# nrf9230_engb_celldsp register map
Vendor: Nordic Semiconductor; Series: nRF92; File version: 1
Registers are 32-bit, read-write, reset 0x0 unless marked. A register's access mark holds for its fields unless they carry their own. Offsets are from the block's base; [hi:lo] are bit positions; lines under a group give offsets from that group; {n}, {i} and the like mark numbered series; 'fields as' and 'values as' point back to an identical list.

## PPIBUS — Programmable Peripheral Interconnect Bus
Base 0x45007000
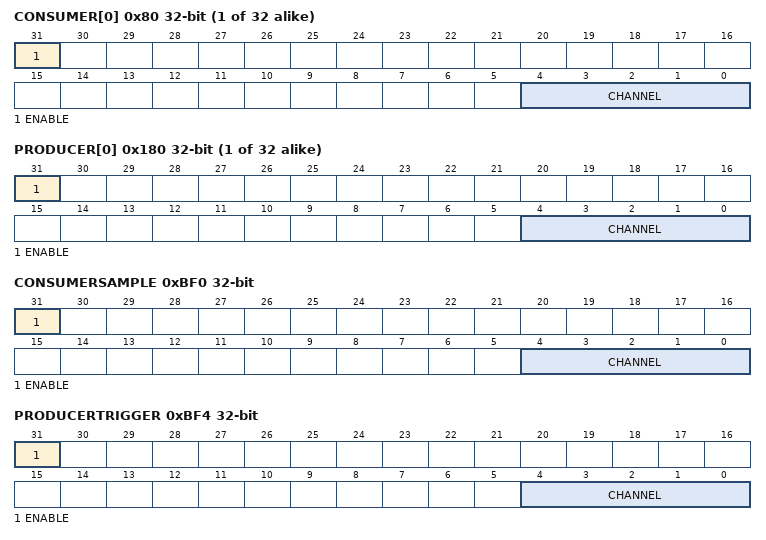
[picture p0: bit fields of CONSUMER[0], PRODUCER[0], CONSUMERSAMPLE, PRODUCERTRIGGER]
{0x80+4i} CONSUMER[{i}] (i=0..31) — Description collection: Configuration for consumer n
  [31] ENABLE — Enable bit for consumer n
  [4:0] CHANNEL — Channel select for consumer n
{0x180+4i} PRODUCER[{i}] (i=0..31) — Description collection: Configuration for producer n
  [31] ENABLE — Enable bit for producer n
  [4:0] CHANNEL — Channel select for producer n
0xBF0 CONSUMERSAMPLE — Configuration for consumer sample register
  [31] ENABLE — Enable bit for consumer sample.
  [4:0] CHANNEL — Channel select for consumer sample.
0xBF4 PRODUCERTRIGGER — Configuration for producer trigger register
  [31] ENABLE — Enable bit for producer trigger.
  [4:0] CHANNEL — Channel select for producer trigger.
0xBF8 SAMPLETASK
  [0] SAMPLETASK — Will sample incoming pulse on ppiBusConsumer[CONSUMERSAMPLE]. Cleared by writing 1'b0.
0xBFC TRIGGEREVENT wo
  [0] TRIGGEREVENT — Will trigger pulse on ppiBusProducer[PRODUCERTRIGGER].

## DSPINTMAP — DSP interrupt mapper
Base 0x45008000
0x504 OFFSET reset 0x100000 — Address offset for IRQ destination address
0x508 ADDRESSINCREMENT reset 0x200 — Address increment for IRQ destination address
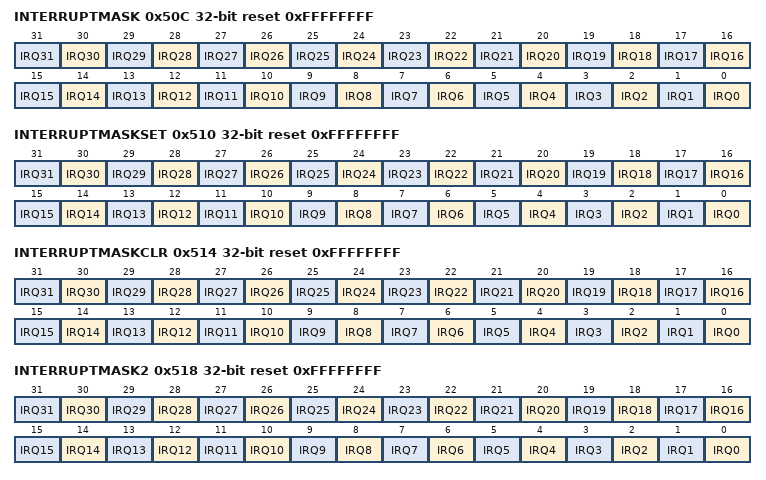
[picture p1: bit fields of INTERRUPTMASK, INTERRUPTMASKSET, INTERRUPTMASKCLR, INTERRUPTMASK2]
0x50C INTERRUPTMASK reset 0xFFFFFFFF — Write interrupt mask for interrupts 0 to 31
  [all] fields
    0=Low (IRQ[i] is unmasked); 1=High (IRQ[i] is masked)
  [n] IRQ{n} (n=0..31) — Mask or unmask interrupt IRQ[i]
0x510 INTERRUPTMASKSET reset 0xFFFFFFFF write-1-sets — Set individual mask bits in interrupt mask for interrupts 0 to 31
  [all] fields
    on read: 0=Low (Read: IRQ[i] is unmasked); 1=High (Read: IRQ[i] is masked) | on write: 1=Set (Write: writing a '1' sets the mask on; writing a '0' has no effect)
  [n] IRQ{n} (n=0..31) — Write '1' to mask IRQ[i]
0x514 INTERRUPTMASKCLR reset 0xFFFFFFFF write-1-clears — Clear individual mask bits in interrupt mask for interrupts 0 to 31
  [all] fields
    on read: 0=Low (Read: IRQ[i] is unmasked); 1=High (Read: IRQ{i] is masked) | on write: 1=Clear (Write: writing a '1' sets the mask off; writing a '0' has no effect)
  [n] IRQ{n} (n=0..31) — Write '1' to unmask IRQ[i]
0x518 INTERRUPTMASK2 reset 0xFFFFFFFF — Write interrupt mask for interrupts 32 to max 63
  fields as INTERRUPTMASK
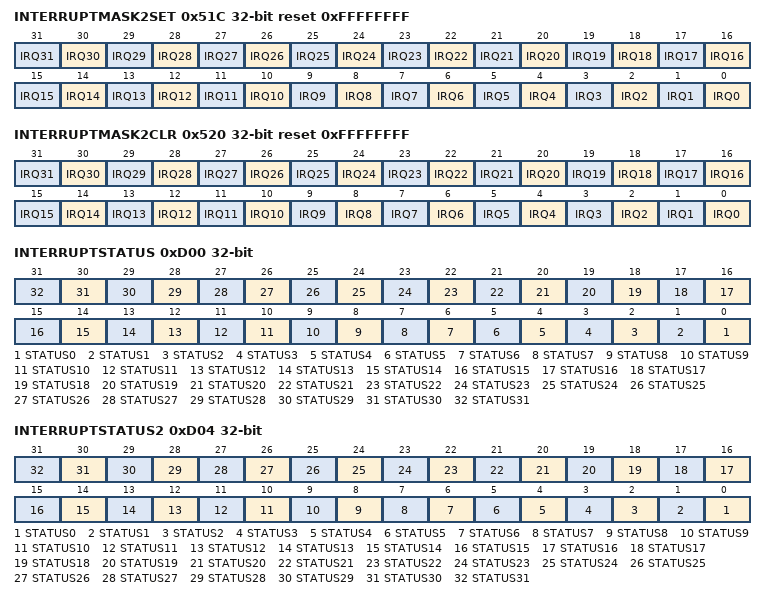
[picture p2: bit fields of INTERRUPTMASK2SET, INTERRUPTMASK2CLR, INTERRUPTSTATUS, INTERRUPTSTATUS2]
0x51C INTERRUPTMASK2SET reset 0xFFFFFFFF write-1-sets — Set individual mask bits in interrupt mask for interrupts 32 to max 63
  fields as INTERRUPTMASKSET
0x520 INTERRUPTMASK2CLR reset 0xFFFFFFFF write-1-clears — Clear individual mask bits in interrupt mask for interrupts 32 to max 63
  [all] fields
    on read: 0=Low (Read: IRQ[i] is unmasked); 1=High (Read: IRQ[i] is masked) | on write: 1=Clear (Write: writing a '1' sets the mask off; writing a '0' has no effect)
  [n] IRQ{n} (n=0..31) — Write '1' to unmask IRQ[i]
{0x524+4i} INTERRUPTPRIORITY[{i}] (i=0..63) — Description collection: Priority of interrupt IRQ[n]
  [2:0] PRIORITY — Interrupt priority
    0=Highest priority; 7=Lowest priority
0xD00 INTERRUPTSTATUS ro — Status of interrupts 0 to 31. Indicates that an IRQ is sent to DSP, but not yet cleared.
  [all] fields
    0=Low (IRQ[i] is cleared); 1=High (IRQ[i] is pending)
  [n] STATUS{n} (n=0..31) — Status of interrupt
0xD04 INTERRUPTSTATUS2 ro — Status of interrupts 32 to max 63. Indicates that an IRQ is sent to DSP, but not yet cleared.
  fields as INTERRUPTSTATUS

## PPIB0 — PPIB APB registers 0
Base 0x4500E000
Same registers: PPIB1 0x45016000
{0x0+4i} TASKS_SEND[{i}] (i=0..31) wo — Description collection: This task is unused, but the PPIB provides the SUBSCRIBE task to connect SEND [n] task.
  [0] TASKS_SEND — This task is unused, but the PPIB provides the SUBSCRIBE task to connect SEND [n] task.
    1=Trigger task
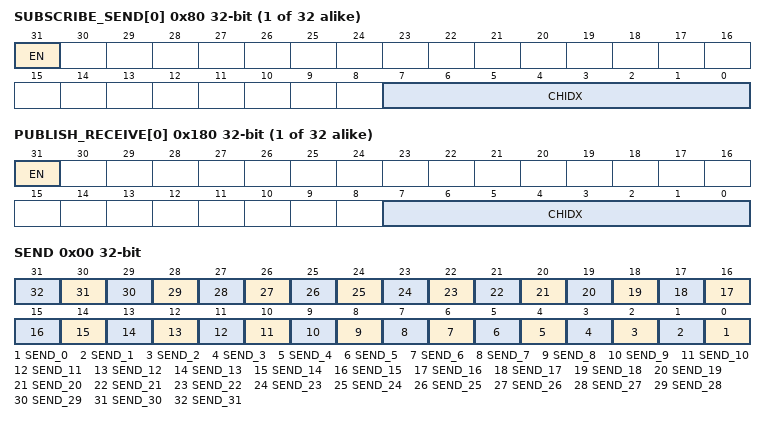
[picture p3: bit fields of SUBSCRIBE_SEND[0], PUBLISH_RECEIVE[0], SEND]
{0x80+4i} SUBSCRIBE_SEND[{i}] (i=0..31) — Description collection: Subscribe configuration for task SEND[n]
  [31] EN
    0=Disabled (Disable subscription); 1=Enabled (Enable subscription)
  [7:0] CHIDX — DPPI channel that task SEND[n] will subscribe to
{0x100+4i} EVENTS_RECEIVE[{i}] (i=0..31) — Description collection: This event is unused, but the PPIB provides the PUBLISH event to connect RECEIVE [n] event.
  [0] EVENTS_RECEIVE — This event is unused, but the PPIB provides the PUBLISH event to connect RECEIVE [n] event.
    0=NotGenerated (Event not generated); 1=Generated (Event generated)
{0x180+4i} PUBLISH_RECEIVE[{i}] (i=0..31) — Description collection: Publish configuration for event RECEIVE[n]
  [31] EN
    0=Disabled (Disable publishing); 1=Enabled (Enable publishing)
  [7:0] CHIDX — DPPI channel that event RECEIVE[n] will publish to
0x400 OVERFLOW group — Unspecified
  0x00 SEND — The task overflow for SEND tasks using SUBSCRIBE_SEND. Write 0 to clear.
    [all] fields
      1=Overflow (Task overflow is happened.); 0=NoOverflow (Task overflow is not happened.)
    [n] SEND_{n} (n=0..31) — The status for tasks overflow at SUBSCRIBE_SEND[{n}].

## Notices in the file
Copyright (c) 2010 - 2024, Nordic Semiconductor ASA
All rights reserved.
Redistribution and use in source and binary forms, with or without modification,
are permitted provided that the following conditions are met:
1. Redistributions of source code must retain the above copyright notice, this
list of conditions and the following disclaimer.
2. Redistributions in binary form, except as embedded into a Nordic
Semiconductor ASA integrated circuit in a product or a software update for
such product, must reproduce the above copyright notice, this list of
conditions and the following disclaimer in the documentation and/or other
materials provided with the distribution.
3. Neither the name of Nordic Semiconductor ASA nor the names of its
contributors may be used to endorse or promote products derived from this
software without specific prior written permission.
4. This software, with or without modification, must only be used with a
Nordic Semiconductor ASA integrated circuit.
5. Any software provided in binary form under this license must not be reverse
engineered, decompiled, modified and/or disassembled.
THIS SOFTWARE IS PROVIDED BY NORDIC SEMICONDUCTOR ASA "AS IS" AND ANY EXPRESS
OR IMPLIED WARRANTIES, INCLUDING, BUT NOT LIMITED TO, THE IMPLIED WARRANTIES
OF MERCHANTABILITY, NONINFRINGEMENT, AND FITNESS FOR A PARTICULAR PURPOSE ARE
DISCLAIMED. IN NO EVENT SHALL NORDIC SEMICONDUCTOR ASA OR CONTRIBUTORS BE
LIABLE FOR ANY DIRECT, INDIRECT, INCIDENTAL, SPECIAL, EXEMPLARY, OR
CONSEQUENTIAL DAMAGES (INCLUDING, BUT NOT LIMITED TO, PROCUREMENT OF SUBSTITUTE
GOODS OR SERVICES; LOSS OF USE, DATA, OR PROFITS; OR BUSINESS INTERRUPTION)
HOWEVER CAUSED AND ON ANY THEORY OF LIABILITY, WHETHER IN CONTRACT, STRICT
LIABILITY, OR TORT (INCLUDING NEGLIGENCE OR OTHERWISE) ARISING IN ANY WAY OUT
OF THE USE OF THIS SOFTWARE, EVEN IF ADVISED OF THE POSSIBILITY OF SUCH DAMAGE.
